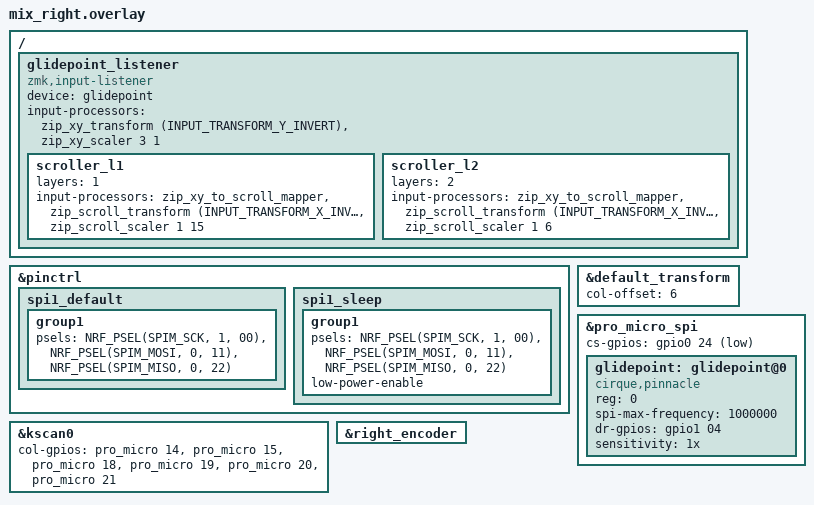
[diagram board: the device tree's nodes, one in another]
/*
 * Copyright (c) 2020 Pete Johanson
 *
 * SPDX-License-Identifier: MIT
 */

#include "mix.dtsi"

#include <dt-bindings/zmk/outputs.h>
#include <zephyr/dt-bindings/input/input-event-codes.h>
#include <input/processors.dtsi>
#include <dt-bindings/zmk/input_transform.h>
#include <dt-bindings/zmk/ext_power.h>
#include <dt-bindings/zmk/pointing.h>



&pinctrl {
    /* configuration for spi1 device, default state */
    spi1_default: spi1_default {
        /* node name is arbitrary */
        group1 {
            psels = <NRF_PSEL(SPIM_SCK,  1, 00)>,
                    <NRF_PSEL(SPIM_MOSI, 0, 11)>,
                    <NRF_PSEL(SPIM_MISO, 0, 22)>;
        };
    };

    /* configuration for spi1 device, sleep state */
    spi1_sleep: spi1_sleep {
        group1 {
            psels = <NRF_PSEL(SPIM_SCK, 1, 00)>,
                    <NRF_PSEL(SPIM_MOSI, 0, 11)>,
                    <NRF_PSEL(SPIM_MISO, 0, 22)>;
            low-power-enable;
        };
    };

};




&default_transform {
    col-offset = <6>;
};


&kscan0 {
    col-gpios
        = <&pro_micro 14 GPIO_ACTIVE_HIGH>
        , <&pro_micro 15 GPIO_ACTIVE_HIGH>
        , <&pro_micro 18 GPIO_ACTIVE_HIGH>
        , <&pro_micro 19 GPIO_ACTIVE_HIGH>
        , <&pro_micro 20 GPIO_ACTIVE_HIGH>
        , <&pro_micro 21 GPIO_ACTIVE_HIGH>
        ;
};


&pro_micro_spi {
    status = "okay";
    cs-gpios = <&gpio0 24 GPIO_ACTIVE_LOW>;

    glidepoint: glidepoint@0 {
        compatible = "cirque,pinnacle";
        reg = <0>;
        spi-max-frequency = <1000000>;
        status = "okay";
        dr-gpios = <&gpio1 04 (GPIO_ACTIVE_HIGH)>;

        sensitivity = "1x";
        //sleep;
        // no-taps;
    };
};

/ {
    glidepoint_listener {
        compatible = "zmk,input-listener";
        device = <&glidepoint>;
        input-processors = 
        <&zip_xy_transform (INPUT_TRANSFORM_Y_INVERT)>,
        <&zip_xy_scaler 3 1>;
        scroller_l1 {
            layers = <1>;
            input-processors =
                <&zip_xy_to_scroll_mapper>,
                <&zip_scroll_transform (INPUT_TRANSFORM_X_INVERT)>,
                <&zip_scroll_scaler 1 15>;
        };
        scroller_l2 {
            layers = <2>;
            input-processors =
                <&zip_xy_to_scroll_mapper>,
                <&zip_scroll_transform (INPUT_TRANSFORM_X_INVERT)>,
                <&zip_scroll_scaler 1 6>;
        };
    }; 
};

&right_encoder {
    status = "okay";
};
